# R7FA6M2AF register map
Vendor: Renesas; Series: RA6; File version: 1.2
CPU: CM4 r0p1, little endian, MPU, FPU, VTOR, 4 interrupt priority bits
Registers are 8-bit, read-write, reset 0x0 unless marked. A register's access mark holds for its fields unless they carry their own. Offsets are from the block's base; [hi:lo] are bit positions.

## PORT0 — Port 0 Control Registers
Base 0x40040000
Same registers: PORT5 0x400400A0, PORT6 0x400400C0, PORT7 0x400400E0, PORT8 0x40040100, PORT9 0x40040120, PORTA 0x40040140, PORTB 0x40040160
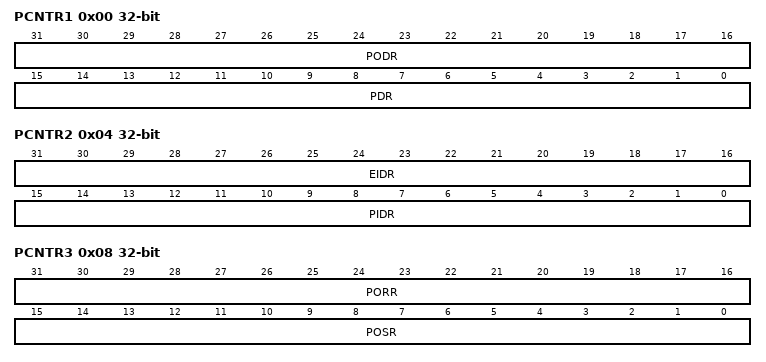
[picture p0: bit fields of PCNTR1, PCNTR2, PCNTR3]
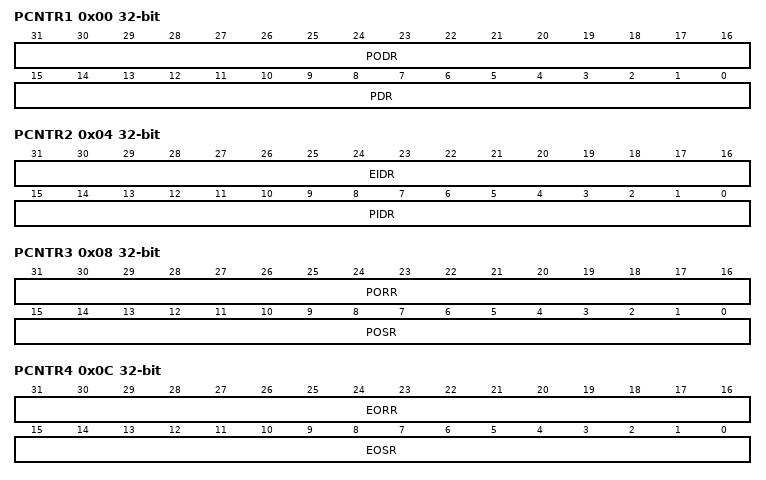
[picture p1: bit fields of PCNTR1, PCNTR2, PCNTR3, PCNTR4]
0x00 PCNTR1 32-bit — Port Control Register 1
  [31:16] PODR — Pmn Output Data
  [15:0] PDR — Pmn Direction
0x00 PODR 16-bit (alternate view of PCNTR1) — Output data register
  [15:0] PODR — Pmn Output Data
0x02 PDR 16-bit (alternate view of PCNTR1) — Data direction register
  [15:0] PDR — Pmn Direction
0x04 PCNTR2 32-bit ro (reset mask 0xFFFF0000) — Port Control Register 2
  [31:16] EIDR — Pmn Event Input Data
  [15:0] PIDR — Pmn Input Data
0x06 PIDR 16-bit ro reset not defined (alternate view of PCNTR2) — Input data register
  [15:0] PIDR — Pmn Input Data
0x08 PCNTR3 32-bit wo — Port Control Register 3
  [31:16] PORR — Pmn Output Reset
  [15:0] POSR — Pmn Output Set
0x08 PORR 16-bit wo (alternate view of PCNTR3) — Output reset register
  [15:0] PORR — Pmn Output Reset
0x0A POSR 16-bit wo (alternate view of PCNTR3) — Output set register
  [15:0] POSR — Pmn Output Set

## PORT1 — Port 1 Control Registers
Base 0x40040020
Same registers: PORT2 0x40040040, PORT3 0x40040060, PORT4 0x40040080
0x00 PCNTR1 32-bit — Port Control Register 1
  [31:16] PODR — Pmn Output Data
  [15:0] PDR — Pmn Direction
0x00 PODR 16-bit (alternate view of PCNTR1) — Output data register
  [15:0] PODR — Pmn Output Data
0x02 PDR 16-bit (alternate view of PCNTR1) — Data direction register
  [15:0] PDR — Pmn Direction
0x04 PCNTR2 32-bit ro (reset mask 0xFFFF0000) — Port Control Register 2
  [31:16] EIDR — Pmn Event Input Data
  [15:0] PIDR — Pmn Input Data
0x04 EIDR 16-bit ro reset not defined (alternate view of PCNTR2) — Event input data register
  [15:0] EIDR — Pmn Event Input Data
0x06 PIDR 16-bit ro reset not defined (alternate view of PCNTR2) — Input data register
  [15:0] PIDR — Pmn Input Data
0x08 PCNTR3 32-bit wo — Port Control Register 3
  [31:16] PORR — Pmn Output Reset
  [15:0] POSR — Pmn Output Set
0x08 PORR 16-bit wo (alternate view of PCNTR3) — Output set register
  [15:0] PORR — Pmn Output Reset
0x0A POSR 16-bit wo (alternate view of PCNTR3) — Output reset register
  [15:0] POSR — Pmn Output Set
0x0C PCNTR4 32-bit — Port Control Register 4
  [31:16] EORR — Pmn Event Output Reset
  [15:0] EOSR — Pmn Event Output Set
0x0C EORR 16-bit (alternate view of PCNTR4) — Event output set register
  [15:0] EORR — Pmn Event Output Reset
0x0E EOSR 16-bit (alternate view of PCNTR4) — Event output reset register
  [15:0] EOSR — Pmn Event Output Set

## PMISC — Miscellaneous Port Control Register
Base 0x40040D00
0x00 PFENET — Ethernet Control Register
  [4] PHYMODE0 — Ethernet Mode Setting ch0
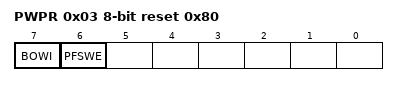
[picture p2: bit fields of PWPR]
0x03 PWPR reset 0x80 — Write,Protect Register
  [7] BOWI — PFSWE Bit Write Disable
  [6] PFSWE — PFS Register Write Enable

## GPT_OPS — Output Phase Switching Controller
Base 0x40078FF0
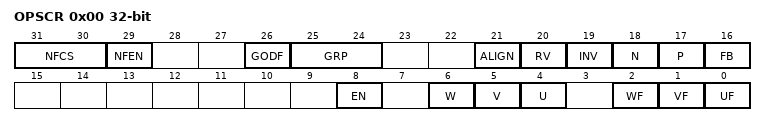
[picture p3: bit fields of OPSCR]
0x00 OPSCR 32-bit — Output Phase Switching Control Register
  [31:30] NFCS — External Input Noise Filter Clock selectionNoise filter sampling clock setting of the external input.
  [29] NFEN — External Input Noise Filter Enable
  [26] GODF — Group output disable function
  [25:24] GRP — Output disabled source selection
  [21] ALIGN — Input phase alignment
  [20] RV — Output phase rotation direction reversal
  [19] INV — Invert,Phase Output Control
  [18] N — Negative,Phase Output (N) Control
  [17] P — Positive,Phase Output (P) Control
  [16] FB — External Feedback Signal EnableThis bit selects the input phase from the software settings and external input.
  [8] EN — Enable,Phase Output Control
  [6] W ro — Input W,Phase MonitorThis bit monitors the state of the input phase.OPSCR.FB=0:External input monitoring by PCLKOPSCR.FB=1:Software settings (UF/VF/WF)
  [5] V ro — Input V,Phase MonitorThis bit monitors the state of the input phase.OPSCR.FB=0:External input monitoring by PCLKOPSCR.FB=1:Software settings (UF/VF/WF)
  [4] U ro — Input U,Phase MonitorThis bit monitors the state of the input phase.OPSCR.FB=0:External input monitoring by PCLKOPSCR.FB=1:Software settings (UF/VF/WF)
  [2] WF — Input Phase Soft Setting UFThis bit sets the input phase by the software settings.This bit setting is valid when the OPSCR.FB bit = 1.
  [1] VF — Input Phase Soft Setting VFThis bit sets the input phase by the software settings.This bit setting is valid when the OPSCR.FB bit = 1.
  [0] UF — Input Phase Soft Setting WFThis bit sets the input phase by the software settings.This bit setting is valid when the OPSCR.FB bit = 1.
